# MDR32F02_rev2 register map
File version: 2.0
CPU: BM-310S, little endian
Registers are 32-bit, read-write, no defined reset value unless marked. A register's access mark holds for its fields unless they carry their own. Offsets are from the block's base; [hi:lo] are bit positions; {n}, {i} and the like mark numbered series; 'fields as' and 'values as' point back to an identical list.

## PORTA — PORTA description
Base 0x40080000
Same registers: PORTB 0x40088000, PORTC 0x40090000, PORTD 0x400F0000
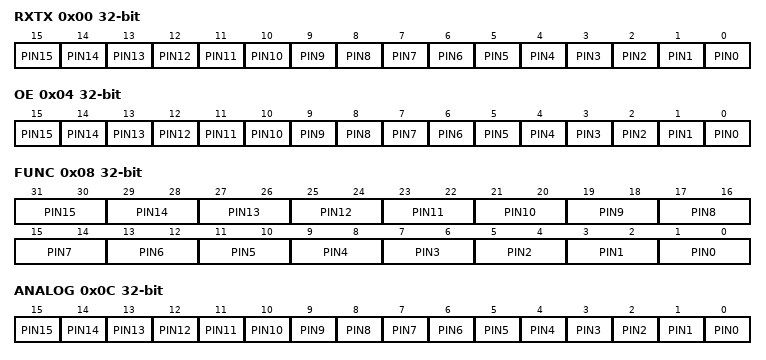
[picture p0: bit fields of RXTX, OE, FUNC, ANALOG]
0x00 RXTX — RXTX description
  [n] PIN{n} (n=0..15) — PIN{n} description
0x04 OE — OE description
  [n] PIN{n} (n=0..15) — PIN{n} description
0x08 FUNC — FUNC description
  [2n+1:2n] PIN{n} (n=0..15) — PIN{n} description
0x0C ANALOG — ANALOG description
  [n] PIN{n} (n=0..15) — PIN{n} description
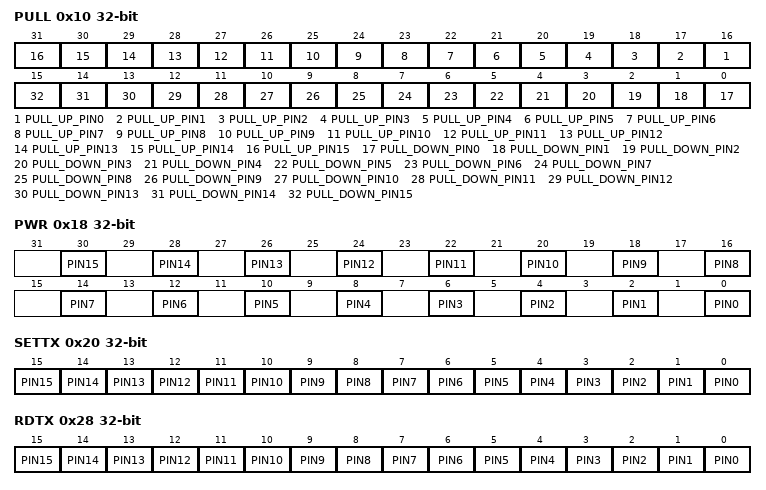
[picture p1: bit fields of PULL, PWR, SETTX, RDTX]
0x10 PULL — PULL description
  [n+16] PULL_UP_PIN{n} (n=0..15) — PULL_UP_PIN{n} description. Rev2
  [n] PULL_DOWN_PIN{n} (n=0..15) — PULL_DOWN_PIN{n} description
0x18 PWR — PWR description
  [2n] PIN{n} (n=0..15) — PIN{n} description
0x20 SETTX — SETTX description
  [n] PIN{n} (n=0..15) — PIN{n} description
0x24 CLRTX access not given — CLRTX description
0x28 RDTX ro — RDTX description
  [n] PIN{n} (n=0..15) — PIN{n} description

## CRC — CRC description
Base 0x40098000
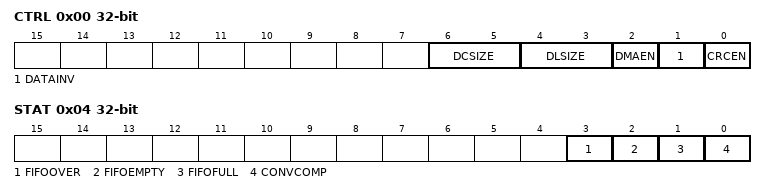
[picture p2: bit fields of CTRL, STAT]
0x00 CTRL — CTRL description
  [6:5] DCSIZE — DCSIZE description
  [4:3] DLSIZE — DLSIZE description
  [2] DMAEN — DMAEN description
  [1] DATAINV — DATAINV description
  [0] CRCEN — CRCEN description
0x04 STAT — STAT description
  [3] FIFOOVER — FIFOOVER description
  [2] FIFOEMPTY — FIFOEMPTY description
  [1] FIFOFULL — FIFOFULL description
  [0] CONVCOMP — CONVCOMP description
0x08 DATAI wo — DATAI description
  [31:0] DATA_IN — DATA_IN description
0x0C VAL — VAL description
  [15:0] CRCOUT — CRCOUT description
0x10 POL — POL description
  [16:0] CRC_POL — CRC_POL description

## SENSORS — SENSORS description
Base 0x400A8000
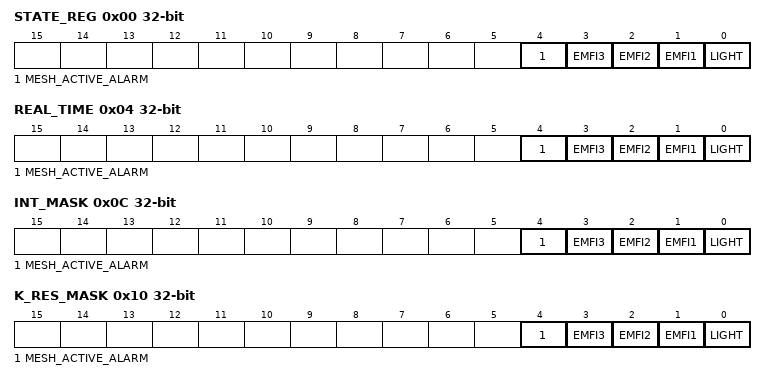
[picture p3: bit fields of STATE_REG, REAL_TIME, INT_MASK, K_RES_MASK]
0x00 STATE_REG — Sensor Signal Status Register
  [4] MESH_ACTIVE_ALARM — MESH_ACTIVE_ALARM description
  [3] EMFI3 — EMFI3 description
  [2] EMFI2 — EMFI2 description
  [1] EMFI1 — EMFI1 description
  [0] LIGHT — LIGHT description
0x04 REAL_TIME — Sensor Input Status Monitoring Register
  fields as STATE_REG
0x0C INT_MASK rw-once — Interrupt Request Mask Register
  fields as STATE_REG
0x10 K_RES_MASK rw-once — Reset Request Mask Register
  fields as STATE_REG
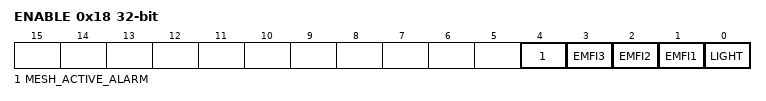
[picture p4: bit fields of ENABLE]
0x18 ENABLE rw-once — Sensor Enable Register
  fields as STATE_REG
0x1C MESH_KEY7 — Active Mesh Key Register 0 (bits 255:224)
0x20 MESH_KEY6 — Active Mesh Key Register 1 (bits 223:192)
0x24 MESH_KEY5 — Active Mesh Key Register 2 (bits 191:160)
0x28 MESH_KEY4 — Active Mesh Key Register 3 (bits 159:128)
0x2C MESH_KEY3 — Active Mesh Key Register 4 (bits 127:96)
0x30 MESH_KEY2 — Active Mesh Key Register 5 (bits 95:64)
0x34 MESH_KEY1 — Active Mesh Key Register 6 (bits 63:32)
0x38 MESH_KEY0 — Active Mesh Key Register 7 (bits 31:0)
0x3C MESH_INIT1 — Active Mesh Init Register 0 (bits 63:32)
0x40 MESH_INIT0 — Active Mesh Init Register 1 (bits 31:0)
0x44 MESHCNTR rw-once — Active Mesh Control Register
  [2:0] DIV — DIV description

## CLK_MEASURE — CLK_MEASURE description
Base 0x400B0000
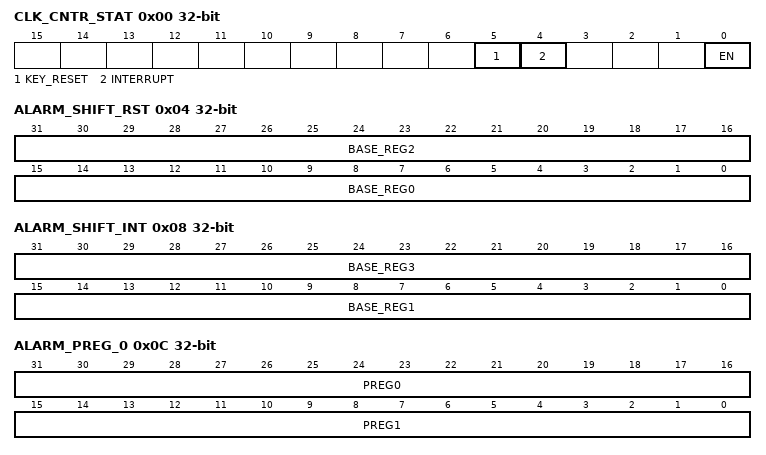
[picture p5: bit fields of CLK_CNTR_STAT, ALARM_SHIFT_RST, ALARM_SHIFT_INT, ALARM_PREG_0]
0x00 CLK_CNTR_STAT — Control and Status Register
  [5] KEY_RESET — KEY_RESET description
  [4] INTERRUPT — INTERRUPT description
  [0] EN — EN description
0x04 ALARM_SHIFT_RST — Reset Treshold Register
  [31:16] BASE_REG2 — BASE_REG2 description
  [15:0] BASE_REG0 — BASE_REG0 description
0x08 ALARM_SHIFT_INT — Interrupt Treshold Register
  [31:16] BASE_REG3 — BASE_REG3 description
  [15:0] BASE_REG1 — BASE_REG1 description
0x0C ALARM_PREG_0 — Counters Reset Control Register 0
  [31:16] PREG0 — PREG0 description
  [15:0] PREG1 — PREG1 description
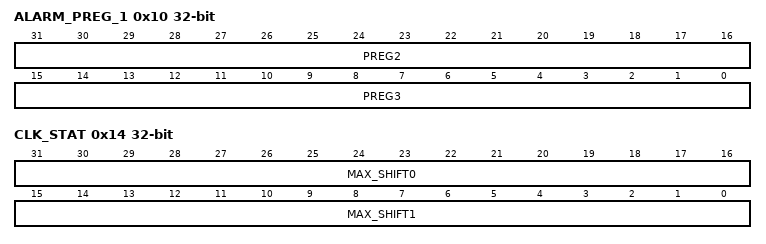
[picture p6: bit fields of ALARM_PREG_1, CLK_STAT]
0x10 ALARM_PREG_1 — Counters Reset Control Register 1
  [31:16] PREG2 — PREG2 description
  [15:0] PREG3 — PREG3 description
0x14 CLK_STAT ro — Maximum SHIFT_REG Value Register
  [31:16] MAX_SHIFT0 — MAX_SHIFT0 description
  [15:0] MAX_SHIFT1 — MAX_SHIFT1 description

## RANDOM — RANDOM description
Base 0x400B8000
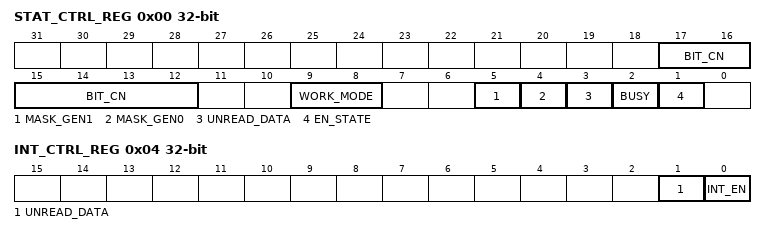
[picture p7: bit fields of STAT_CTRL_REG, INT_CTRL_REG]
0x00 STAT_CTRL_REG — Status and Control Register
  [17:12] BIT_CN ro — BIT_CN description
  [9:8] WORK_MODE — WORK_MODE description
  [5] MASK_GEN1 — MASK_GEN1 description
  [4] MASK_GEN0 — MASK_GEN0 description
  [3] UNREAD_DATA ro — UNREAD_DATA description
  [2] BUSY ro — BUSY description
  [1] EN_STATE ro — EN_STATE description
0x04 INT_CTRL_REG — Interrupt Control Register
  [1] UNREAD_DATA ro — UNREAD_DATA description
  [0] INT_EN — INT_EN description
0x08 CLK_DIV_REG — Clock Divider Register
  [15:0] DIV — DIV description
0x0C PAUSE_REG — Pause Register
0x10 OUTPUT_REG ro — Output Random Register
0x14 PAUSE_CNT_REG ro — Pause Counter Register
0x18 TEMP_REG ro — Temp Random Register
